# TC3567C register map
File version: 0.1
CPU: CM0 r0p0, little endian, no MPU, no FPU, 4 interrupt priority bits
Registers are 32-bit, read-write, no defined reset value unless marked. A register's access mark holds for its fields unless they carry their own. Offsets are from the block's base; [hi:lo] are bit positions.

## BluetoothCounter
Base 0x40040240
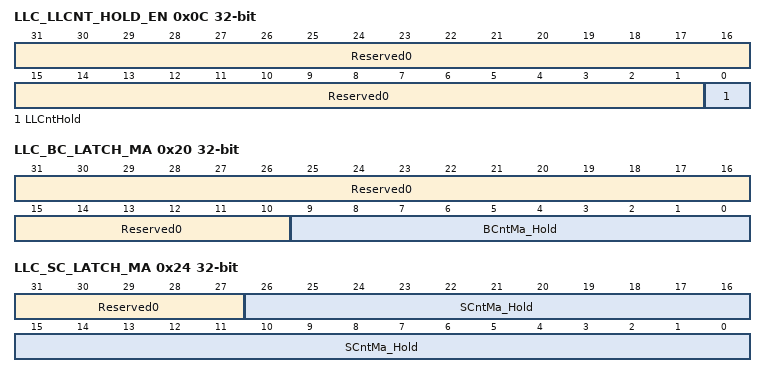
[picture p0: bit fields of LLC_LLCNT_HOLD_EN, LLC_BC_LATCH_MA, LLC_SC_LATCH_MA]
0x0C LLC_LLCNT_HOLD_EN — Hold Bluetooth counter
  [31:1] Reserved0 — Do not change the values.
  [0] LLCntHold — When 0 (or arbitrary value) is set this register, the following registers will hold the values: LLC_BC_LATCH_MA:Master Bit Counter LLC_SC_LATCH_MA:Master Slot Counter Before accessing LLC_BC_LATCH_MA or LLC_SC_LATCH_MA, please set 0 (or arbitrary value) to this register.
0x20 LLC_BC_LATCH_MA ro — Holding Master Bit Counter
  [31:10] Reserved0 — Do not change the values.
  [9:0] BCntMa_Hold rw — Master bit counter value. "Master slot counter" counts up every 1 micro seconds. When this value is 624, this value becomes 0 and SCntMa_Hold value counts up on next count up timing. Before reading this value, please set 0 (or arbitrary value) to LLCntHold.
0x24 LLC_SC_LATCH_MA — Holding Master Slot Counter
  [31:27] Reserved0 — Do not change the values.
  [26:0] SCntMa_Hold — Master slot counter value. "Master slot counter" counts up every 1 slot (625 micro seconds). Before reading this value, please set 0 (or arbitrary value) to LLCntHold.

## TimerBCG — Timer (BCTimer, GTimer)
Base 0x4004D000
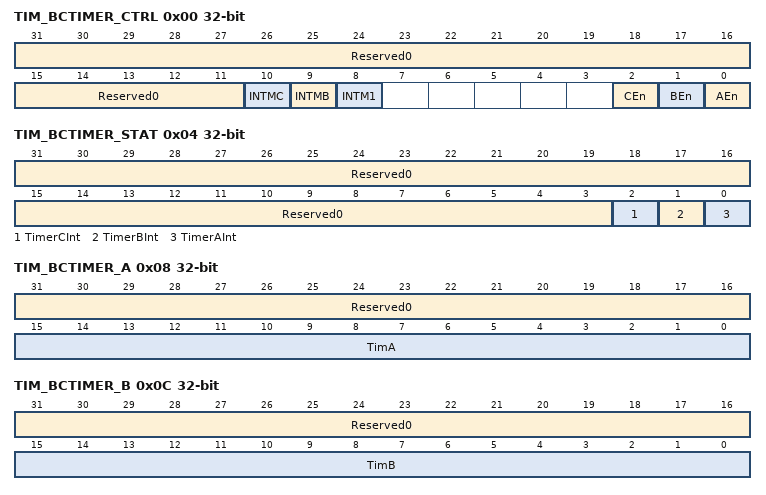
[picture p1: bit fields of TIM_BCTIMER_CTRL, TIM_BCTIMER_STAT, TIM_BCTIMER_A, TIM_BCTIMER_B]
0x00 TIM_BCTIMER_CTRL — Bit Clock Timer Control
  [31:11] Reserved0 ro — Do not change the values.
  [10] INTMC — Timer C Interrupt mask 0: the interrupt is not masked 1: the interutpt is masked
  [9] INTMB — Timer B Interrupt mask 0: the interrupt is not masked 1: the interutpt is masked
  [8] INTM1 — Timer A Interrupt mask 0: the interrupt is not masked 1: the interutpt is masked
  [2] CEn — Enable autoreload feature for timer C 0: Stop when Timer C gets 0. 1: Reload the initial value when Timer C gets 0.
  [1] BEn — Enable autoreload feature for timer B 0: Stop when Timer B gets 0. 1: Reload the initial value when Timer B gets 0.
  [0] AEn — Enable autoreload feature for timer A 0: Stop when Timer A gets 0. 1: Reload the initial value when Timer A gets 0.
0x04 TIM_BCTIMER_STAT — Bit Clock Timer Status
  [31:3] Reserved0 ro — Do not change the values.
  [2] TimerCInt — Interrupt from Timer C 0: No interrupt from Timer C. 1: Interrupt from Timer C exist.
  [1] TimerBInt — Interrupt from Timer B 0: No interrupt from Timer B. 1: Interrupt from Timer B exist.
  [0] TimerAInt — Interrupt from Timer A 0: No interrupt from Timer A. 1: Interrupt from Timer A exist.
0x08 TIM_BCTIMER_A — Bit Clock Timer A control
  [31:16] Reserved0 ro — Do not change the values.
  [15:0] TimA — Start Value Timer A Set the initial value of Timer A.
0x0C TIM_BCTIMER_B — Bit Clock Timer B control
  [31:16] Reserved0 ro — Do not change the values.
  [15:0] TimB — Start Value Timer B Set the initial value of Timer B.
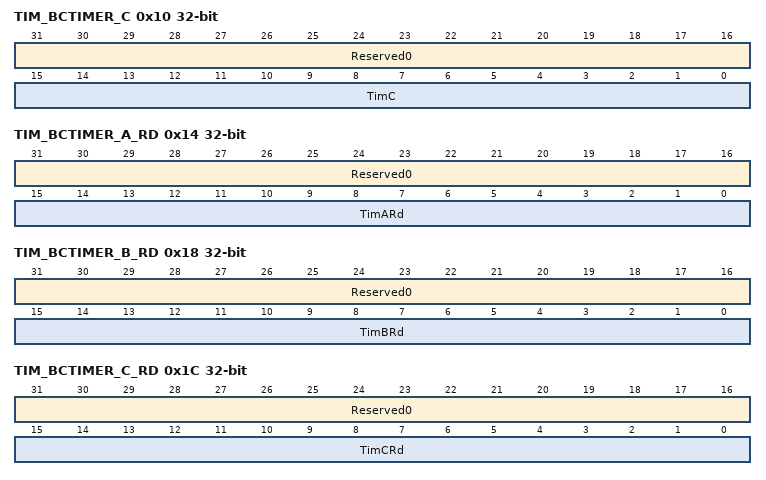
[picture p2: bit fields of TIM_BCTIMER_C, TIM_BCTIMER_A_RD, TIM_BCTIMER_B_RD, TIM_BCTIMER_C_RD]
0x10 TIM_BCTIMER_C — Bit Clock Timer C control
  [31:16] Reserved0 ro — Do not change the values.
  [15:0] TimC — Start Value Timer C Set the initial value of Timer C.
0x14 TIM_BCTIMER_A_RD — Bit Clock Timer A read
  [31:16] Reserved0 ro — Do not change the values.
  [15:0] TimARd — Current Value of Timer A
0x18 TIM_BCTIMER_B_RD — Bit Clock Timer B read
  [31:16] Reserved0 ro — Do not change the values.
  [15:0] TimBRd — Current Value of Timer B
0x1C TIM_BCTIMER_C_RD — Bit Clock Timer C read
  [31:16] Reserved0 ro — Do not change the values.
  [15:0] TimCRd — Current Value of Timer C
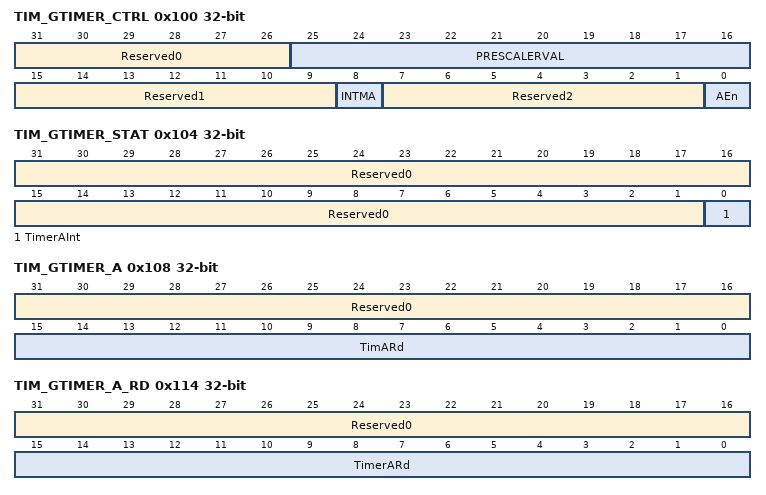
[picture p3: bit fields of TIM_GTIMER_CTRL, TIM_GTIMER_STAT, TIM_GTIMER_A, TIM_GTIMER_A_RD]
0x100 TIM_GTIMER_CTRL — Timer Control
  [31:26] Reserved0 ro — Do not change the values.
  [25:16] PRESCALERVAL — Settings for frequency divider of TimerSCLK to generate timer clock. 0x000 : No divide 0x001 : 1/2 0x002 : 1/3 ........ 0x3ff : 1/1024
  [15:9] Reserved1 ro — Do not change the values.
  [8] INTMA — Timer A Interrupt mask 0: the interrupt is not masked 1: the interutpt is masked
  [7:1] Reserved2 ro — Do not change the values.
  [0] AEn — Enable auto reload feature for Timer A
0x104 TIM_GTIMER_STAT — Timer Status
  [31:1] Reserved0 — Do not change the values.
  [0] TimerAInt — Interrutp bit from Timer A 0: No interrupt from Timer A. 1: Interrupt from Timer A exist.
0x108 TIM_GTIMER_A — Timer Initial Value
  [31:16] Reserved0 ro — Do not change the values.
  [15:0] TimARd — Start Value of TimerA.
0x114 TIM_GTIMER_A_RD — Timer Value read
  [31:16] Reserved0 — Do not change the values.
  [15:0] TimerARd — Current Value of Timer A.
